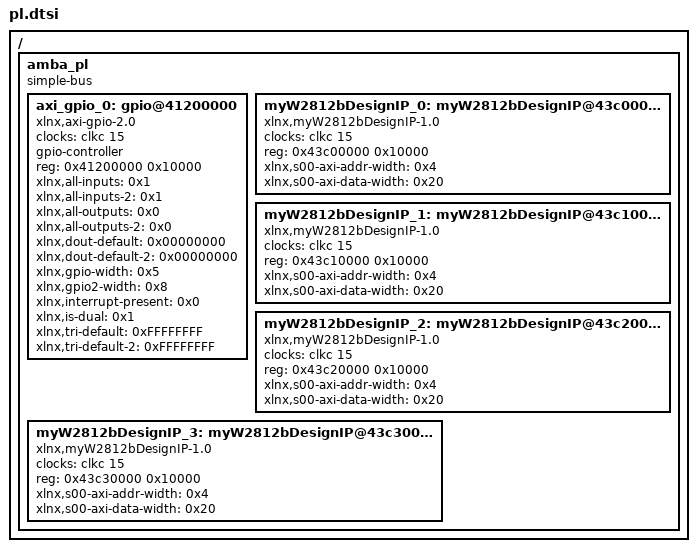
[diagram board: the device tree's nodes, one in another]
/*
 * CAUTION: This file is automatically generated by Xilinx.
 * Version:  
 * Today is: Sat Feb 27 16:52:10 2021
 */


/ {
	amba_pl: amba_pl {
		#address-cells = <1>;
		#size-cells = <1>;
		compatible = "simple-bus";
		ranges ;
		axi_gpio_0: gpio@41200000 {
			#gpio-cells = <3>;
			clock-names = "s_axi_aclk";
			clocks = <&clkc 15>;
			compatible = "xlnx,axi-gpio-2.0", "xlnx,xps-gpio-1.00.a";
			gpio-controller ;
			reg = <0x41200000 0x10000>;
			xlnx,all-inputs = <0x1>;
			xlnx,all-inputs-2 = <0x1>;
			xlnx,all-outputs = <0x0>;
			xlnx,all-outputs-2 = <0x0>;
			xlnx,dout-default = <0x00000000>;
			xlnx,dout-default-2 = <0x00000000>;
			xlnx,gpio-width = <0x5>;
			xlnx,gpio2-width = <0x8>;
			xlnx,interrupt-present = <0x0>;
			xlnx,is-dual = <0x1>;
			xlnx,tri-default = <0xFFFFFFFF>;
			xlnx,tri-default-2 = <0xFFFFFFFF>;
		};
		myW2812bDesignIP_0: myW2812bDesignIP@43c00000 {
			clock-names = "s00_axi_aclk";
			clocks = <&clkc 15>;
			compatible = "xlnx,myW2812bDesignIP-1.0";
			reg = <0x43c00000 0x10000>;
			xlnx,s00-axi-addr-width = <0x4>;
			xlnx,s00-axi-data-width = <0x20>;
		};
		myW2812bDesignIP_1: myW2812bDesignIP@43c10000 {
			clock-names = "s00_axi_aclk";
			clocks = <&clkc 15>;
			compatible = "xlnx,myW2812bDesignIP-1.0";
			reg = <0x43c10000 0x10000>;
			xlnx,s00-axi-addr-width = <0x4>;
			xlnx,s00-axi-data-width = <0x20>;
		};
		myW2812bDesignIP_2: myW2812bDesignIP@43c20000 {
			clock-names = "s00_axi_aclk";
			clocks = <&clkc 15>;
			compatible = "xlnx,myW2812bDesignIP-1.0";
			reg = <0x43c20000 0x10000>;
			xlnx,s00-axi-addr-width = <0x4>;
			xlnx,s00-axi-data-width = <0x20>;
		};
		myW2812bDesignIP_3: myW2812bDesignIP@43c30000 {
			clock-names = "s00_axi_aclk";
			clocks = <&clkc 15>;
			compatible = "xlnx,myW2812bDesignIP-1.0";
			reg = <0x43c30000 0x10000>;
			xlnx,s00-axi-addr-width = <0x4>;
			xlnx,s00-axi-data-width = <0x20>;
		};
	};
};
